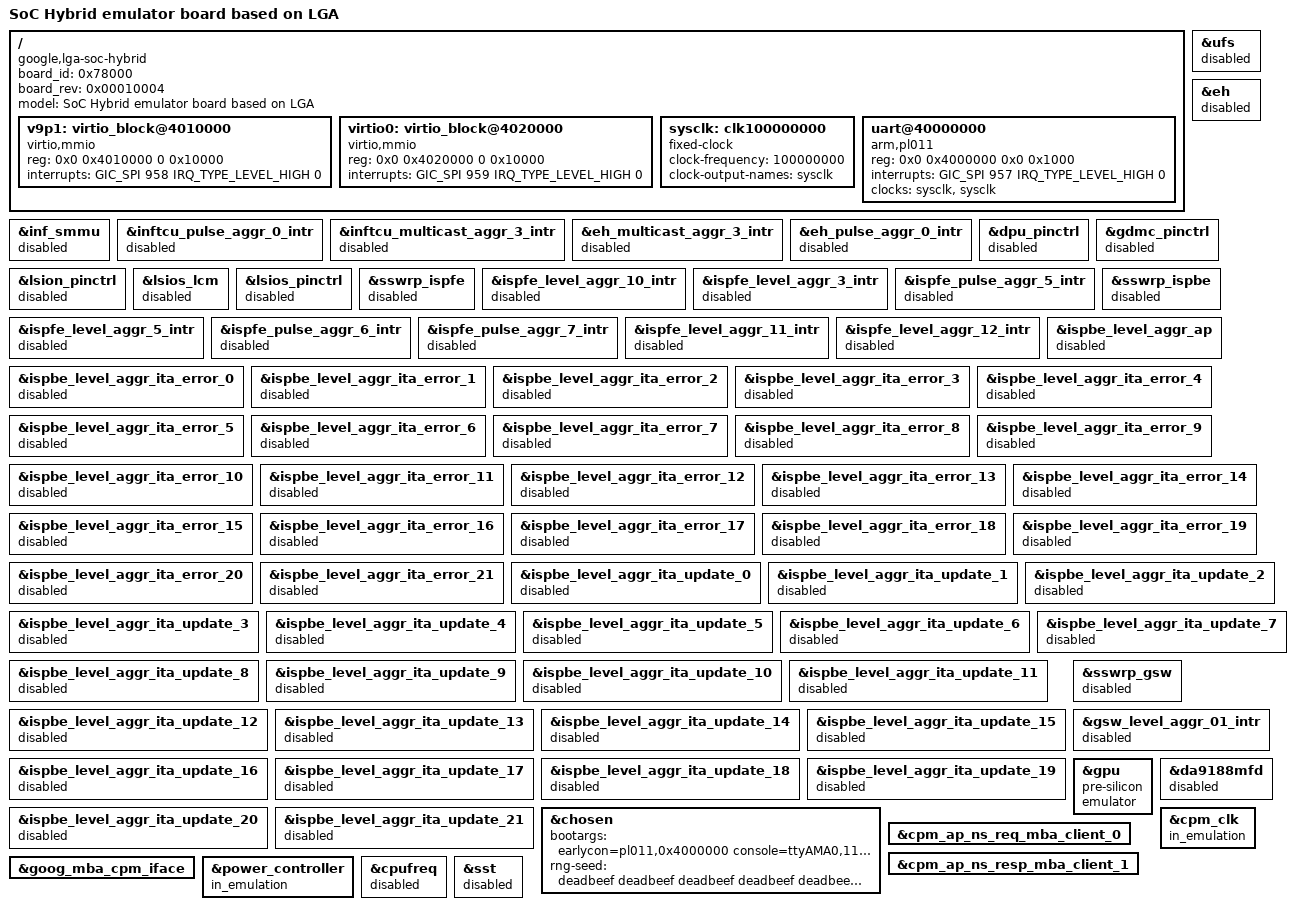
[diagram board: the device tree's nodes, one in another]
// SPDX-License-Identifier: GPL-2.0-only
/*
 * Deepspace device tree source
 *
 * Copyright 2023 Google LLC
 */

/dts-v1/;
/plugin/;

#define BATTERY_EEPROM_1K

#include "lga-deepspace-pinctrl.dtsi"
#include <dt-bindings/interrupt-controller/arm-gic.h>
#include "lga-deepspace-coresight-disabled.dtsi"

/ {
	board_id = <0x78000>;
	board_rev = <0x00010004>;
	fragment@boardbase {
		target-path = "/";
		__overlay__ {
			model = "SoC Hybrid emulator board based on LGA";
			compatible = "google,lga-soc-hybrid", "google,lga-soc-hybrid-emulator";
		};
	};
};

/ {
	fragment@virt_dp {
		target-path = "/";
		__overlay__ {
			v9p1: virtio_block@4010000 {
				compatible = "virtio,mmio";
				reg = <0x0 0x4010000 0 0x10000>;
				interrupts = <GIC_SPI 958 IRQ_TYPE_LEVEL_HIGH 0>;
			};

			// Virtio block for loading images
			virtio0: virtio_block@4020000 {
				compatible = "virtio,mmio";
				reg = <0x0 0x4020000 0 0x10000>;
				interrupts = <GIC_SPI 959 IRQ_TYPE_LEVEL_HIGH 0>;
			};
		};
	};

	fragment@virt_uart {
		target-path = "/";
		// Virtualized uart
		__overlay__ {
			sysclk: clk100000000 {
				compatible = "fixed-clock";
				#clock-cells = <0>;
				clock-frequency = <100000000>;
				clock-output-names = "sysclk";
			};
			// soc-hybrid platform uses arm pl011 uart
			uart@40000000 {
				compatible = "arm,pl011", "arm,primecell";
				reg = <0x0 0x4000000 0x0 0x1000>;
				interrupts = <GIC_SPI 957 IRQ_TYPE_LEVEL_HIGH 0>;
				clock-names = "uartclk", "apb_pclk";
				clocks = <&sysclk>, <&sysclk>;
			};
		};
	};
};

// Disable UFS nodes, we don't support UFS on soc-hybrid platform
&ufs {
	status = "disabled";
};

&inf_smmu {
	status = "disabled";
};

&inftcu_pulse_aggr_0_intr {
	status = "disabled";
};

&inftcu_multicast_aggr_3_intr {
	status = "disabled";
};

// Disable eh nodes for soc-hybrid platform
&eh {
	status = "disabled";
};

&eh_multicast_aggr_3_intr {
	status = "disabled";
};

&eh_pulse_aggr_0_intr {
	status = "disabled";
};

// Disable a few things that are known to be problematic on SoC hybrid now.
// TODO(b/291686880): Restore the node when ready.
&dpu_pinctrl {
	status = "disabled";
};
&gdmc_pinctrl {
	status = "disabled";
};
&lsion_pinctrl {
	status = "disabled";
};
&lsios_lcm {
	status = "disabled";
};
&lsios_pinctrl {
	status = "disabled";
};

/* Disable ISPFE & ISPBE nodes as CPM firmware does not support powering on ISP */
&sswrp_ispfe {
	status = "disabled";
};

&ispfe_level_aggr_10_intr {
	status = "disabled";
};

&ispfe_level_aggr_3_intr {
	status = "disabled";
};

&ispfe_pulse_aggr_5_intr {
	status = "disabled";
};

&ispfe_level_aggr_5_intr {
	status = "disabled";
};

&ispfe_pulse_aggr_6_intr {
	status = "disabled";
};

&ispfe_pulse_aggr_7_intr {
	status = "disabled";
};

&ispfe_level_aggr_11_intr {
	status = "disabled";
};

&ispfe_level_aggr_12_intr {
	status = "disabled";
};

&sswrp_ispbe {
	status = "disabled";
};

&ispbe_level_aggr_ap {
	status = "disabled";
};

&ispbe_level_aggr_ita_error_0 {
	status = "disabled";
};

&ispbe_level_aggr_ita_error_1 {
	status = "disabled";
};

&ispbe_level_aggr_ita_error_2 {
	status = "disabled";
};

&ispbe_level_aggr_ita_error_3 {
	status = "disabled";
};

&ispbe_level_aggr_ita_error_4 {
	status = "disabled";
};

&ispbe_level_aggr_ita_error_5 {
	status = "disabled";
};

&ispbe_level_aggr_ita_error_6 {
	status = "disabled";
};

&ispbe_level_aggr_ita_error_7 {
	status = "disabled";
};

&ispbe_level_aggr_ita_error_8 {
	status = "disabled";
};

&ispbe_level_aggr_ita_error_9 {
	status = "disabled";
};

&ispbe_level_aggr_ita_error_10 {
	status = "disabled";
};

&ispbe_level_aggr_ita_error_11 {
	status = "disabled";
};

&ispbe_level_aggr_ita_error_12 {
	status = "disabled";
};

&ispbe_level_aggr_ita_error_13 {
	status = "disabled";
};

&ispbe_level_aggr_ita_error_14 {
	status = "disabled";
};

&ispbe_level_aggr_ita_error_15 {
	status = "disabled";
};

&ispbe_level_aggr_ita_error_16 {
	status = "disabled";
};

&ispbe_level_aggr_ita_error_17 {
	status = "disabled";
};

&ispbe_level_aggr_ita_error_18 {
	status = "disabled";
};

&ispbe_level_aggr_ita_error_19 {
	status = "disabled";
};

&ispbe_level_aggr_ita_error_20 {
	status = "disabled";
};

&ispbe_level_aggr_ita_error_21 {
	status = "disabled";
};

&ispbe_level_aggr_ita_update_0 {
	status = "disabled";
};

&ispbe_level_aggr_ita_update_1 {
	status = "disabled";
};

&ispbe_level_aggr_ita_update_2 {
	status = "disabled";
};

&ispbe_level_aggr_ita_update_3 {
	status = "disabled";
};

&ispbe_level_aggr_ita_update_4 {
	status = "disabled";
};

&ispbe_level_aggr_ita_update_5 {
	status = "disabled";
};

&ispbe_level_aggr_ita_update_6 {
	status = "disabled";
};

&ispbe_level_aggr_ita_update_7 {
	status = "disabled";
};

&ispbe_level_aggr_ita_update_8 {
	status = "disabled";
};

&ispbe_level_aggr_ita_update_9 {
	status = "disabled";
};

&ispbe_level_aggr_ita_update_10 {
	status = "disabled";
};

&ispbe_level_aggr_ita_update_11 {
	status = "disabled";
};

&ispbe_level_aggr_ita_update_12 {
	status = "disabled";
};

&ispbe_level_aggr_ita_update_13 {
	status = "disabled";
};

&ispbe_level_aggr_ita_update_14 {
	status = "disabled";
};

&ispbe_level_aggr_ita_update_15 {
	status = "disabled";
};

&ispbe_level_aggr_ita_update_16 {
	status = "disabled";
};

&ispbe_level_aggr_ita_update_17 {
	status = "disabled";
};

&ispbe_level_aggr_ita_update_18 {
	status = "disabled";
};

&ispbe_level_aggr_ita_update_19 {
	status = "disabled";
};

&ispbe_level_aggr_ita_update_20 {
	status = "disabled";
};

&ispbe_level_aggr_ita_update_21 {
	status = "disabled";
};

/* Disable unsupported sswrp on default soc-hybrid build */
&sswrp_gsw {
	status = "disabled";
};

&gsw_level_aggr_01_intr {
	status = "disabled";
};

&chosen {
	bootargs = "earlycon=pl011,0x4000000 console=ttyAMA0,115200n8 norandmaps ro androidboot.force_normal_boot=1 androidboot.hardware.platform=gem5 loglevel=8 init=/init maxcpus=1 androidboot.boot_devices=4020000.virtio_block enforcing=0 pvrsrvkm.FabricCoherencyOverride=0 printk.devkmsg=on firmware_class.path=/vendor/firmware fw_devlink=rpm androidboot.selinux=permissive deferred_probe_timeout=50";
	/* hardcode rng seed for gem5 */
	rng-seed = "deadbeef deadbeef deadbeef deadbeef deadbeef deadbeef /
		    deadbeef deadbeef deadbeef deadbeef deadbeef deadbeef /
		    deadbeef deadbeef deadbeef deadbeef deadbeef deadbeef";
};

&gpu {
	pre-silicon;
	emulator;
};

&cpm_ap_ns_req_mba_client_0 {
	status = "okay";
};

&cpm_ap_ns_resp_mba_client_1 {
	status = "okay";
};

&goog_mba_cpm_iface {
	status = "okay";
};

/* Zebu have no working PMIC RTL, disable all PMIC drivers. */
&da9188mfd {
	status = "disabled";
};

/* Config setting for power-controller on emu platform. */
&power_controller {
	in_emulation;
};

/* Config setting for cpm_clk on emu platform. */
&cpm_clk {
	in_emulation;
};

/* Disable cpufreq because it generates KP on SoC Hybrid. */
&cpufreq {
	status = "disabled";
};


/* No plan to enable deeper CPU low power modes on LGA pre-silicon. */
&sst {
	status = "disabled";
};
